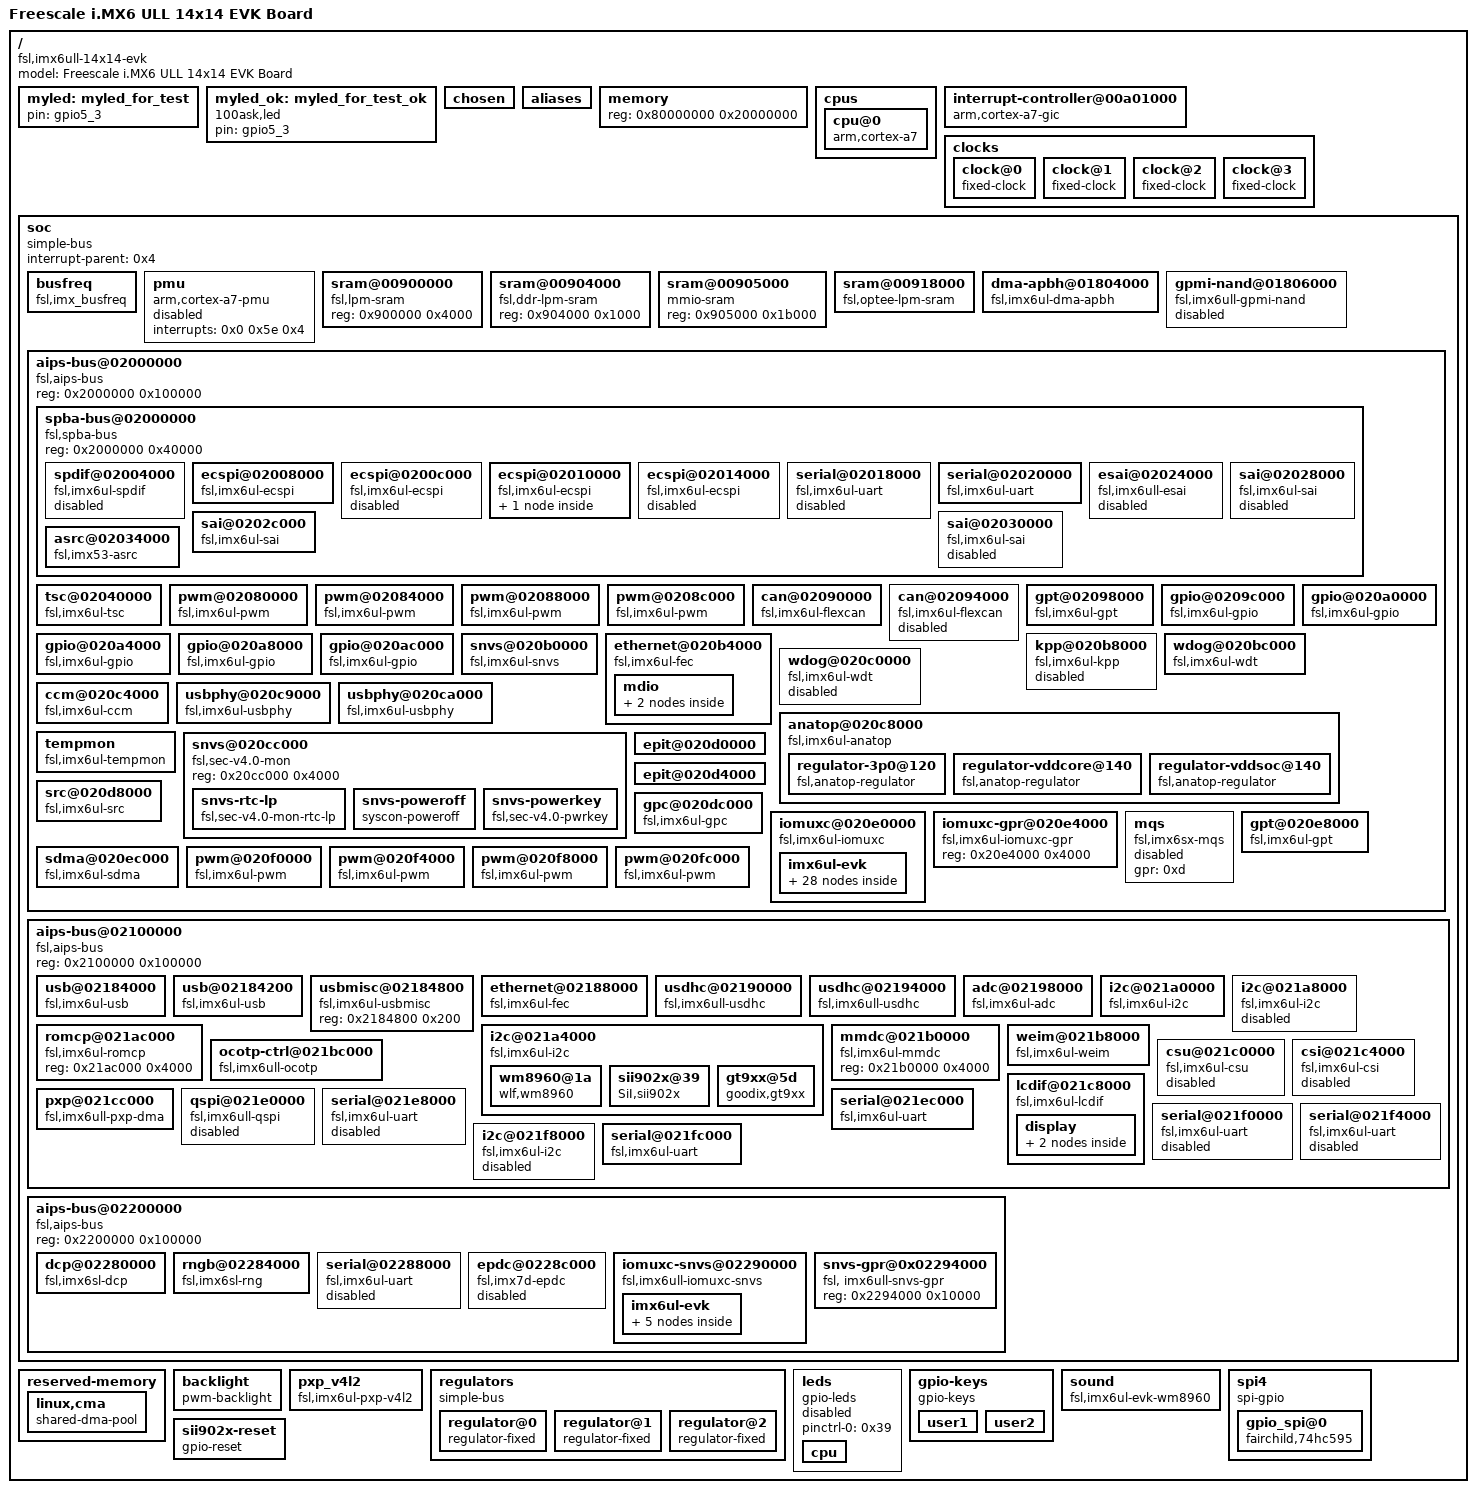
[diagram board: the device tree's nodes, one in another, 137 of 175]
/dts-v1/;

/ {
	#address-cells = <0x1>;
	#size-cells = <0x1>;
	model = "Freescale i.MX6 ULL 14x14 EVK Board";
	compatible = "fsl,imx6ull-14x14-evk", "fsl,imx6ull";

	myled: myled_for_test {
		pin = "gpio5_3";
	};

	myled_ok: myled_for_test_ok {
		compatible = "100ask,led";
		pin = "gpio5_3";
	};

	chosen {
		stdout-path = "/soc/aips-bus@02000000/spba-bus@02000000/serial@02020000";
	};

	aliases {
		can0 = "/soc/aips-bus@02000000/can@02090000";
		can1 = "/soc/aips-bus@02000000/can@02094000";
		ethernet0 = "/soc/aips-bus@02100000/ethernet@02188000";
		ethernet1 = "/soc/aips-bus@02000000/ethernet@020b4000";
		gpio0 = "/soc/aips-bus@02000000/gpio@0209c000";
		gpio1 = "/soc/aips-bus@02000000/gpio@020a0000";
		gpio2 = "/soc/aips-bus@02000000/gpio@020a4000";
		gpio3 = "/soc/aips-bus@02000000/gpio@020a8000";
		gpio4 = "/soc/aips-bus@02000000/gpio@020ac000";
		i2c0 = "/soc/aips-bus@02100000/i2c@021a0000";
		i2c1 = "/soc/aips-bus@02100000/i2c@021a4000";
		i2c2 = "/soc/aips-bus@02100000/i2c@021a8000";
		i2c3 = "/soc/aips-bus@02100000/i2c@021f8000";
		mmc0 = "/soc/aips-bus@02100000/usdhc@02190000";
		mmc1 = "/soc/aips-bus@02100000/usdhc@02194000";
		serial0 = "/soc/aips-bus@02000000/spba-bus@02000000/serial@02020000";
		serial1 = "/soc/aips-bus@02100000/serial@021e8000";
		serial2 = "/soc/aips-bus@02100000/serial@021ec000";
		serial3 = "/soc/aips-bus@02100000/serial@021f0000";
		serial4 = "/soc/aips-bus@02100000/serial@021f4000";
		serial5 = "/soc/aips-bus@02100000/serial@021fc000";
		serial6 = "/soc/aips-bus@02000000/spba-bus@02000000/serial@02018000";
		serial7 = "/soc/aips-bus@02200000/serial@02288000";
		spi0 = "/soc/aips-bus@02000000/spba-bus@02000000/ecspi@02008000";
		spi1 = "/soc/aips-bus@02000000/spba-bus@02000000/ecspi@0200c000";
		spi2 = "/soc/aips-bus@02000000/spba-bus@02000000/ecspi@02010000";
		spi3 = "/soc/aips-bus@02000000/spba-bus@02000000/ecspi@02014000";
		usbphy0 = "/soc/aips-bus@02000000/usbphy@020c9000";
		usbphy1 = "/soc/aips-bus@02000000/usbphy@020ca000";
	};

	memory {
		device_type = "memory";
		reg = <0x80000000 0x20000000>;
	};

	cpus {
		#address-cells = <0x1>;
		#size-cells = <0x0>;

		cpu@0 {
			compatible = "arm,cortex-a7";
			device_type = "cpu";
			reg = <0x0>;
			clock-latency = <0xee6c>;
			operating-points = <0xdbba0 0x137478 0xc15c0 0x12b128 0x80e80 0x11edd8 0x60ae0 0xfa3e8 0x30570 0xe7ef0>;
			fsl,soc-operating-points = <0xdbba0 0x11edd8 0xc15c0 0x11edd8 0x80e80 0x11edd8 0x60ae0 0x11edd8 0x30570 0x11edd8>;
			fsl,low-power-run;
			clocks = <0x1 0x5d 0x1 0x1a 0x1 0x26 0x1 0xdb 0x1 0x38 0x1 0x39 0x1 0x19 0x1 0x12 0x1 0xb 0x1 0x4 0x1 0x3>;
			clock-names = "arm", "pll2_bus", "pll2_pfd2_396m", "secondary_sel", "step", "pll1_sw", "pll1_sys", "pll1_bypass", "pll1", "pll1_bypass_src", "osc";
			arm-supply = <0x2>;
			soc-supply = <0x3>;
		};
	};

	interrupt-controller@00a01000 {
		compatible = "arm,cortex-a7-gic";
		#interrupt-cells = <0x3>;
		interrupt-controller;
		reg = <0xa01000 0x1000 0xa02000 0x100>;
		linux,phandle = <0x1e>;
		phandle = <0x1e>;
	};

	clocks {
		#address-cells = <0x1>;
		#size-cells = <0x0>;

		clock@0 {
			compatible = "fixed-clock";
			reg = <0x0>;
			#clock-cells = <0x0>;
			clock-frequency = <0x8000>;
			clock-output-names = "ckil";
			linux,phandle = <0x16>;
			phandle = <0x16>;
		};

		clock@1 {
			compatible = "fixed-clock";
			reg = <0x1>;
			#clock-cells = <0x0>;
			clock-frequency = <0x16e3600>;
			clock-output-names = "osc";
			linux,phandle = <0x17>;
			phandle = <0x17>;
		};

		clock@2 {
			compatible = "fixed-clock";
			reg = <0x2>;
			#clock-cells = <0x0>;
			clock-frequency = <0x0>;
			clock-output-names = "ipp_di0";
			linux,phandle = <0x18>;
			phandle = <0x18>;
		};

		clock@3 {
			compatible = "fixed-clock";
			reg = <0x3>;
			#clock-cells = <0x0>;
			clock-frequency = <0x0>;
			clock-output-names = "ipp_di1";
			linux,phandle = <0x19>;
			phandle = <0x19>;
		};
	};

	soc {
		#address-cells = <0x1>;
		#size-cells = <0x1>;
		compatible = "simple-bus";
		interrupt-parent = <0x4>;
		ranges;

		busfreq {
			compatible = "fsl,imx_busfreq";
			clocks = <0x1 0x26 0x1 0x35 0x1 0x1a 0x1 0x5d 0x1 0x1b 0x1 0x55 0x1 0x3c 0x1 0x5e 0x1 0x3e 0x1 0x3 0x1 0x60 0x1 0xd4 0x1 0x56 0x1 0x3d 0x1 0x5f 0x1 0x3f 0x1 0x38 0x1 0xa3 0x1 0x4 0x1 0x12 0x1 0x19 0x1 0x39 0x1 0xb>;
			clock-names = "pll2_pfd2_396m", "pll2_198m", "pll2_bus", "arm", "pll3_usb_otg", "periph", "periph_pre", "periph_clk2", "periph_clk2_sel", "osc", "ahb", "ocram", "periph2", "periph2_pre", "periph2_clk2", "periph2_clk2_sel", "step", "mmdc", "pll1_bypass_src", "pll1_bypass", "pll1_sys", "pll1_sw", "pll1";
			fsl,max_ddr_freq = <0x17d78400>;
		};

		pmu {
			compatible = "arm,cortex-a7-pmu";
			interrupts = <0x0 0x5e 0x4>;
			status = "disabled";
		};

		sram@00900000 {
			compatible = "fsl,lpm-sram";
			reg = <0x900000 0x4000>;
		};

		sram@00904000 {
			compatible = "fsl,ddr-lpm-sram";
			reg = <0x904000 0x1000>;
		};

		sram@00905000 {
			compatible = "mmio-sram";
			reg = <0x905000 0x1b000>;
			linux,phandle = <0x5>;
			phandle = <0x5>;
		};

		sram@00918000 {
			compatible = "fsl,optee-lpm-sram";
			reg = <0x918000 0x8000>;
			overw_reg = <0x5 0x905000 0x13000>;
		};

		dma-apbh@01804000 {
			compatible = "fsl,imx6ul-dma-apbh", "fsl,imx28-dma-apbh";
			reg = <0x1804000 0x2000>;
			interrupts = <0x0 0xd 0x4 0x0 0xd 0x4 0x0 0xd 0x4 0x0 0xd 0x4>;
			interrupt-names = "gpmi0", "gpmi1", "gpmi2", "gpmi3";
			#dma-cells = <0x1>;
			dma-channels = <0x4>;
			clocks = <0x1 0x80>;
			linux,phandle = <0x6>;
			phandle = <0x6>;
		};

		gpmi-nand@01806000 {
			compatible = "fsl,imx6ull-gpmi-nand", "fsl, imx6ul-gpmi-nand";
			#address-cells = <0x1>;
			#size-cells = <0x1>;
			reg = <0x1806000 0x2000 0x1808000 0x4000>;
			reg-names = "gpmi-nand", "bch";
			interrupts = <0x0 0xf 0x4>;
			interrupt-names = "bch";
			clocks = <0x1 0x85 0x1 0x86 0x1 0x84 0x1 0x83 0x1 0xdc>;
			clock-names = "gpmi_io", "gpmi_apb", "gpmi_bch", "gpmi_bch_apb", "per1_bch";
			dmas = <0x6 0x0>;
			dma-names = "rx-tx";
			status = "disabled";
		};

		aips-bus@02000000 {
			compatible = "fsl,aips-bus", "simple-bus";
			#address-cells = <0x1>;
			#size-cells = <0x1>;
			reg = <0x2000000 0x100000>;
			ranges;

			spba-bus@02000000 {
				compatible = "fsl,spba-bus", "simple-bus";
				#address-cells = <0x1>;
				#size-cells = <0x1>;
				reg = <0x2000000 0x40000>;
				ranges;

				spdif@02004000 {
					compatible = "fsl,imx6ul-spdif", "fsl,imx35-spdif";
					reg = <0x2004000 0x4000>;
					interrupts = <0x0 0x34 0x4>;
					dmas = <0x7 0x29 0x12 0x0 0x7 0x2a 0x12 0x0>;
					dma-names = "rx", "tx";
					clocks = <0x1 0xd5 0x1 0x3 0x1 0xbc 0x1 0x0 0x1 0x0 0x1 0x0 0x1 0x64 0x1 0x0 0x1 0x0 0x1 0xbb>;
					clock-names = "core", "rxtx0", "rxtx1", "rxtx2", "rxtx3", "rxtx4", "rxtx5", "rxtx6", "rxtx7", "spba";
					status = "disabled";
				};

				ecspi@02008000 {
					#address-cells = <0x1>;
					#size-cells = <0x0>;
					compatible = "fsl,imx6ul-ecspi", "fsl,imx51-ecspi";
					reg = <0x2008000 0x4000>;
					interrupts = <0x0 0x1f 0x4>;
					clocks = <0x1 0x8b 0x1 0x8b>;
					clock-names = "ipg", "per";
					dmas = <0x7 0x3 0x7 0x1 0x7 0x4 0x7 0x2>;
					dma-names = "rx", "tx";
					status = "okay";
					pinctrl-names = "default";
					pinctrl-0 = <0x8>;
					fsl,spi-num-chipselects = <0x2>;
					cs-gpios = <0x9 0x1a 0x1 0x9 0x18 0x1>;
				};

				ecspi@0200c000 {
					#address-cells = <0x1>;
					#size-cells = <0x0>;
					compatible = "fsl,imx6ul-ecspi", "fsl,imx51-ecspi";
					reg = <0x200c000 0x4000>;
					interrupts = <0x0 0x20 0x4>;
					clocks = <0x1 0x8c 0x1 0x8c>;
					clock-names = "ipg", "per";
					dmas = <0x7 0x5 0x7 0x1 0x7 0x6 0x7 0x2>;
					dma-names = "rx", "tx";
					status = "disabled";
				};

				ecspi@02010000 {
					#address-cells = <0x1>;
					#size-cells = <0x0>;
					compatible = "fsl,imx6ul-ecspi", "fsl,imx51-ecspi";
					reg = <0x2010000 0x4000>;
					interrupts = <0x0 0x21 0x4>;
					clocks = <0x1 0x8d 0x1 0x8d>;
					clock-names = "ipg", "per";
					dmas = <0x7 0x7 0x7 0x1 0x7 0x8 0x7 0x2>;
					dma-names = "rx", "tx";
					status = "okay";
					pinctrl-names = "default";
					pinctrl-0 = <0xa>;
					cs-gpios = <0xb 0x14 0x1>;

					icm20608@0 {
						compatible = "invensense,icm20608";
						interrupt-parent = <0xb>;
						interrupts = <0x1 0x1>;
						spi-max-frequency = <0x7a1200>;
						reg = <0x0>;
					};
				};

				ecspi@02014000 {
					#address-cells = <0x1>;
					#size-cells = <0x0>;
					compatible = "fsl,imx6ul-ecspi", "fsl,imx51-ecspi";
					reg = <0x2014000 0x4000>;
					interrupts = <0x0 0x22 0x4>;
					clocks = <0x1 0x8e 0x1 0x8e>;
					clock-names = "ipg", "per";
					dmas = <0x7 0x9 0x7 0x1 0x7 0xa 0x7 0x2>;
					dma-names = "rx", "tx";
					status = "disabled";
				};

				serial@02018000 {
					compatible = "fsl,imx6ul-uart", "fsl,imx6q-uart", "fsl,imx21-uart";
					reg = <0x2018000 0x4000>;
					interrupts = <0x0 0x27 0x4>;
					clocks = <0x1 0xc9 0x1 0xca>;
					clock-names = "ipg", "per";
					dmas = <0x7 0x2b 0x4 0x0 0x7 0x2c 0x4 0x0>;
					dma-names = "rx", "tx";
					status = "disabled";
				};

				serial@02020000 {
					compatible = "fsl,imx6ul-uart", "fsl,imx6q-uart", "fsl,imx21-uart";
					reg = <0x2020000 0x4000>;
					interrupts = <0x0 0x1a 0x4>;
					clocks = <0x1 0xbd 0x1 0xbe>;
					clock-names = "ipg", "per";
					status = "okay";
					pinctrl-names = "default";
					pinctrl-0 = <0xc>;
				};

				esai@02024000 {
					compatible = "fsl,imx6ull-esai";
					reg = <0x2024000 0x4000>;
					interrupts = <0x0 0x33 0x4>;
					clocks = <0x1 0xe6 0x1 0xe5 0x1 0xe4 0x1 0xe6 0x1 0xbb>;
					clock-names = "core", "mem", "extal", "fsys", "spba";
					dmas = <0x7 0x0 0x15 0x0 0x7 0x2f 0x15 0x0>;
					dma-names = "rx", "tx";
					dma-source = <0xd 0x0 0xe 0x0 0xf>;
					status = "disabled";
				};

				sai@02028000 {
					compatible = "fsl,imx6ul-sai", "fsl,imx6sx-sai";
					reg = <0x2028000 0x4000>;
					interrupts = <0x0 0x61 0x4>;
					clocks = <0x1 0xb3 0x1 0x0 0x1 0xb2 0x1 0x0 0x1 0x0>;
					clock-names = "bus", "mclk0", "mclk1", "mclk2", "mclk3";
					dma-names = "rx", "tx";
					dmas = <0x7 0x23 0x18 0x0 0x7 0x24 0x18 0x0>;
					status = "disabled";
				};

				sai@0202c000 {
					compatible = "fsl,imx6ul-sai", "fsl,imx6sx-sai";
					reg = <0x202c000 0x4000>;
					interrupts = <0x0 0x62 0x4>;
					clocks = <0x1 0xb5 0x1 0x0 0x1 0xb4 0x1 0x0 0x1 0x0>;
					clock-names = "bus", "mclk0", "mclk1", "mclk2", "mclk3";
					dma-names = "rx", "tx";
					dmas = <0x7 0x25 0x18 0x0 0x7 0x26 0x18 0x0>;
					status = "okay";
					pinctrl-names = "default";
					pinctrl-0 = <0xe>;
					assigned-clocks = <0x1 0x47 0x1 0xb4>;
					assigned-clock-parents = <0x1 0x32>;
					assigned-clock-rates = <0x0 0xbb8000>;
					linux,phandle = <0x3a>;
					phandle = <0x3a>;
				};

				sai@02030000 {
					compatible = "fsl,imx6ul-sai", "fsl,imx6sx-sai";
					reg = <0x2030000 0x4000>;
					interrupts = <0x0 0x18 0x4>;
					clocks = <0x1 0xb7 0x1 0x0 0x1 0xb6 0x1 0x0 0x1 0x0>;
					clock-names = "bus", "mclk0", "mclk1", "mclk2", "mclk3";
					dma-names = "rx", "tx";
					dmas = <0x7 0x27 0x18 0x0 0x7 0x28 0x18 0x0>;
					status = "disabled";
				};

				asrc@02034000 {
					compatible = "fsl,imx53-asrc";
					reg = <0x2034000 0x4000>;
					interrupts = <0x0 0x32 0x4>;
					clocks = <0x1 0x81 0x1 0x82 0x1 0x0 0x1 0x0 0x1 0x0 0x1 0x0 0x1 0x0 0x1 0x0 0x1 0x0 0x1 0x0 0x1 0x0 0x1 0x0 0x1 0x0 0x1 0x0 0x1 0x0 0x1 0xbc 0x1 0x0 0x1 0x0 0x1 0xbb>;
					clock-names = "mem", "ipg", "asrck_0", "asrck_1", "asrck_2", "asrck_3", "asrck_4", "asrck_5", "asrck_6", "asrck_7", "asrck_8", "asrck_9", "asrck_a", "asrck_b", "asrck_c", "asrck_d", "asrck_e", "asrck_f", "spba";
					dmas = <0x7 0x11 0x17 0x1 0x7 0x12 0x17 0x1 0x7 0x13 0x17 0x1 0x7 0x14 0x17 0x1 0x7 0x15 0x17 0x1 0x7 0x16 0x17 0x1>;
					dma-names = "rxa", "rxb", "rxc", "txa", "txb", "txc";
					fsl,asrc-rate = <0xbb80>;
					fsl,asrc-width = <0x10>;
					status = "okay";
					linux,phandle = <0x3c>;
					phandle = <0x3c>;
				};
			};

			tsc@02040000 {
				compatible = "fsl,imx6ul-tsc";
				reg = <0x2040000 0x4000 0x219c000 0x4000>;
				interrupts = <0x0 0x3 0x4 0x0 0x65 0x4>;
				clocks = <0x1 0x64 0x1 0x7c>;
				clock-names = "tsc", "adc";
				status = "okay";
				pinctrl-names = "default";
				pinctrl-0 = <0xf>;
				xnur-gpio = <0xb 0x3 0x1>;
				measure-delay-time = <0xfffff>;
				pre-charge-time = <0xffff>;
			};

			pwm@02080000 {
				compatible = "fsl,imx6ul-pwm", "fsl,imx27-pwm";
				reg = <0x2080000 0x4000>;
				interrupts = <0x0 0x53 0x4>;
				clocks = <0x1 0xa7 0x1 0xa7>;
				clock-names = "ipg", "per";
				#pwm-cells = <0x2>;
				pinctrl-names = "default";
				pinctrl-0 = <0x10>;
				status = "okay";
				linux,phandle = <0x38>;
				phandle = <0x38>;
			};

			pwm@02084000 {
				compatible = "fsl,imx6ul-pwm", "fsl,imx27-pwm";
				reg = <0x2084000 0x4000>;
				interrupts = <0x0 0x54 0x4>;
				clocks = <0x1 0x0 0x1 0x0>;
				clock-names = "ipg", "per";
				#pwm-cells = <0x2>;
			};

			pwm@02088000 {
				compatible = "fsl,imx6ul-pwm", "fsl,imx27-pwm";
				reg = <0x2088000 0x4000>;
				interrupts = <0x0 0x55 0x4>;
				clocks = <0x1 0xa9 0x1 0xa9>;
				clock-names = "ipg", "per";
				#pwm-cells = <0x2>;
			};

			pwm@0208c000 {
				compatible = "fsl,imx6ul-pwm", "fsl,imx27-pwm";
				reg = <0x208c000 0x4000>;
				interrupts = <0x0 0x56 0x4>;
				clocks = <0x1 0x0 0x1 0x0>;
				clock-names = "ipg", "per";
				#pwm-cells = <0x2>;
			};

			can@02090000 {
				compatible = "fsl,imx6ul-flexcan", "fsl,imx6q-flexcan";
				reg = <0x2090000 0x4000>;
				interrupts = <0x0 0x6e 0x4>;
				clocks = <0x1 0x94 0x1 0x95>;
				clock-names = "ipg", "per";
				stop-mode = <0xd 0x10 0x1 0x10 0x11>;
				status = "okay";
				pinctrl-names = "default";
				pinctrl-0 = <0x11>;
				xceiver-supply = <0x12>;
			};

			can@02094000 {
				compatible = "fsl,imx6ul-flexcan", "fsl,imx6q-flexcan";
				reg = <0x2094000 0x4000>;
				interrupts = <0x0 0x6f 0x4>;
				clocks = <0x1 0x96 0x1 0x97>;
				clock-names = "ipg", "per";
				stop-mode = <0xd 0x10 0x2 0x10 0x12>;
				status = "disabled";
			};

			gpt@02098000 {
				compatible = "fsl,imx6ul-gpt", "fsl,imx31-gpt";
				reg = <0x2098000 0x4000>;
				interrupts = <0x0 0x37 0x4>;
				clocks = <0x1 0x98 0x1 0xd6>;
				clock-names = "ipg", "osc_per";
			};

			gpio@0209c000 {
				compatible = "fsl,imx6ul-gpio", "fsl,imx35-gpio";
				reg = <0x209c000 0x4000>;
				interrupts = <0x0 0x42 0x4 0x0 0x43 0x4>;
				gpio-controller;
				#gpio-cells = <0x2>;
				interrupt-controller;
				#interrupt-cells = <0x2>;
				linux,phandle = <0xb>;
				phandle = <0xb>;
			};

			gpio@020a0000 {
				compatible = "fsl,imx6ul-gpio", "fsl,imx35-gpio";
				reg = <0x20a0000 0x4000>;
				interrupts = <0x0 0x44 0x4 0x0 0x45 0x4>;
				gpio-controller;
				#gpio-cells = <0x2>;
				interrupt-controller;
				#interrupt-cells = <0x2>;
			};

			gpio@020a4000 {
				compatible = "fsl,imx6ul-gpio", "fsl,imx35-gpio";
				reg = <0x20a4000 0x4000>;
				interrupts = <0x0 0x46 0x4 0x0 0x47 0x4>;
				gpio-controller;
				#gpio-cells = <0x2>;
				interrupt-controller;
				#interrupt-cells = <0x2>;
				linux,phandle = <0x32>;
				phandle = <0x32>;
			};

			gpio@020a8000 {
				compatible = "fsl,imx6ul-gpio", "fsl,imx35-gpio";
				reg = <0x20a8000 0x4000>;
				interrupts = <0x0 0x48 0x4 0x0 0x49 0x4>;
				gpio-controller;
				#gpio-cells = <0x2>;
				interrupt-controller;
				#interrupt-cells = <0x2>;
				linux,phandle = <0x9>;
				phandle = <0x9>;
			};

			gpio@020ac000 {
				compatible = "fsl,imx6ul-gpio", "fsl,imx35-gpio";
				reg = <0x20ac000 0x4000>;
				interrupts = <0x0 0x4a 0x4 0x0 0x4b 0x4>;
				gpio-controller;
				#gpio-cells = <0x2>;
				interrupt-controller;
				#interrupt-cells = <0x2>;
				linux,phandle = <0x15>;
				phandle = <0x15>;
			};

			snvs@020b0000 {
				compatible = "fsl,imx6ul-snvs";
				reg = <0x20b0000 0x4000>;
				interrupts = <0x0 0x4 0x4>;
			};

			ethernet@020b4000 {
				compatible = "fsl,imx6ul-fec", "fsl,imx6q-fec";
				reg = <0x20b4000 0x4000>;
				interrupts = <0x0 0x78 0x4 0x0 0x79 0x4>;
				clocks = <0x1 0x90 0x1 0x91 0x1 0x30 0x1 0x2e 0x1 0x2e>;
				clock-names = "ipg", "ahb", "ptp", "enet_clk_ref", "enet_out";
				stop-mode = <0xd 0x10 0x4>;
				fsl,num-tx-queues = <0x1>;
				fsl,num-rx-queues = <0x1>;
				fsl,magic-packet;
				fsl,wakeup_irq = <0x0>;
				status = "okay";
				pinctrl-names = "default";
				pinctrl-0 = <0x13>;
				phy-mode = "rmii";
				phy-handle = <0x14>;
				phy-reset-gpios = <0x15 0x6 0x1>;
				phy-reset-duration = <0x1a>;

				mdio {
					#address-cells = <0x1>;
					#size-cells = <0x0>;

					ethernet-phy@0 {
						compatible = "ethernet-phy-ieee802.3-c22";
						smsc,disable-energy-detect;
						reg = <0x0>;
						linux,phandle = <0x24>;
						phandle = <0x24>;
					};

					ethernet-phy@1 {
						compatible = "ethernet-phy-ieee802.3-c22";
						smsc,disable-energy-detect;
						reg = <0x1>;
						linux,phandle = <0x14>;
						phandle = <0x14>;
					};
				};
			};

			kpp@020b8000 {
				compatible = "fsl,imx6ul-kpp", "fsl,imx21-kpp";
				reg = <0x20b8000 0x4000>;
				interrupts = <0x0 0x52 0x4>;
				clocks = <0x1 0x0>;
				status = "disabled";
			};

			wdog@020bc000 {
				compatible = "fsl,imx6ul-wdt", "fsl,imx21-wdt";
				reg = <0x20bc000 0x4000>;
				interrupts = <0x0 0x50 0x4>;
				clocks = <0x1 0xd0>;
				status = "okay";
			};

			wdog@020c0000 {
				compatible = "fsl,imx6ul-wdt", "fsl,imx21-wdt";
				reg = <0x20c0000 0x4000>;
				interrupts = <0x0 0x51 0x4>;
				clocks = <0x1 0xd1>;
				status = "disabled";
			};

			ccm@020c4000 {
				compatible = "fsl,imx6ul-ccm";
				reg = <0x20c4000 0x4000>;
				interrupts = <0x0 0x57 0x4 0x0 0x58 0x4>;
				#clock-cells = <0x1>;
				clocks = <0x16 0x17 0x18 0x19>;
				clock-names = "ckil", "osc", "ipp_di0", "ipp_di1";
				assigned-clocks = <0x1 0x32>;
				assigned-clock-rates = <0x2ee00000>;
				linux,phandle = <0x1>;
				phandle = <0x1>;
			};

			anatop@020c8000 {
				compatible = "fsl,imx6ul-anatop", "fsl,imx6q-anatop", "syscon", "simple-bus";
				reg = <0x20c8000 0x1000>;
				interrupts = <0x0 0x31 0x4 0x0 0x36 0x4 0x0 0x7f 0x4>;
				linux,phandle = <0x1b>;
				phandle = <0x1b>;

				regulator-3p0@120 {
					compatible = "fsl,anatop-regulator";
					regulator-name = "vdd3p0";
					regulator-min-microvolt = <0x280de8>;
					regulator-max-microvolt = <0x33e140>;
					anatop-reg-offset = <0x120>;
					anatop-vol-bit-shift = <0x8>;
					anatop-vol-bit-width = <0x5>;
					anatop-min-bit-val = <0x0>;
					anatop-min-voltage = <0x280de8>;
					anatop-max-voltage = <0x33e140>;
					anatop-enable-bit = <0x0>;
					linux,phandle = <0x1a>;
					phandle = <0x1a>;
				};

				regulator-vddcore@140 {
					compatible = "fsl,anatop-regulator";
					regulator-name = "cpu";
					regulator-min-microvolt = <0xb1008>;
					regulator-max-microvolt = <0x162010>;
					regulator-always-on;
					anatop-reg-offset = <0x140>;
					anatop-vol-bit-shift = <0x0>;
					anatop-vol-bit-width = <0x5>;
					anatop-delay-reg-offset = <0x170>;
					anatop-delay-bit-shift = <0x18>;
					anatop-delay-bit-width = <0x2>;
					anatop-min-bit-val = <0x1>;
					anatop-min-voltage = <0xb1008>;
					anatop-max-voltage = <0x162010>;
					linux,phandle = <0x2>;
					phandle = <0x2>;
				};

				regulator-vddsoc@140 {
					compatible = "fsl,anatop-regulator";
					regulator-name = "vddsoc";
					regulator-min-microvolt = <0xb1008>;
					regulator-max-microvolt = <0x162010>;
					regulator-always-on;
					anatop-reg-offset = <0x140>;
					anatop-vol-bit-shift = <0x12>;
					anatop-vol-bit-width = <0x5>;
					anatop-delay-reg-offset = <0x170>;
					anatop-delay-bit-shift = <0x1c>;
					anatop-delay-bit-width = <0x2>;
					anatop-min-bit-val = <0x1>;
					anatop-min-voltage = <0xb1008>;
					anatop-max-voltage = <0x162010>;
					linux,phandle = <0x3>;
					phandle = <0x3>;
				};
			};

			usbphy@020c9000 {
				compatible = "fsl,imx6ul-usbphy", "fsl,imx23-usbphy";
				reg = <0x20c9000 0x1000>;
				interrupts = <0x0 0x2c 0x4>;
				clocks = <0x1 0x20>;
				phy-3p0-supply = <0x1a>;
				fsl,anatop = <0x1b>;
				tx-d-cal = <0x5>;
				linux,phandle = <0x20>;
				phandle = <0x20>;
			};

			usbphy@020ca000 {
				compatible = "fsl,imx6ul-usbphy", "fsl,imx23-usbphy";
				reg = <0x20ca000 0x1000>;
				interrupts = <0x0 0x2d 0x4>;
				clocks = <0x1 0x21>;
				phy-3p0-supply = <0x1a>;
				fsl,anatop = <0x1b>;
				tx-d-cal = <0x5>;
				linux,phandle = <0x22>;
				phandle = <0x22>;
			};

			tempmon {
				compatible = "fsl,imx6ul-tempmon", "fsl,imx6sx-tempmon";
				interrupts = <0x0 0x31 0x4>;
				fsl,tempmon = <0x1b>;
				fsl,tempmon-data = <0x1c>;
				clocks = <0x1 0x1b>;
			};

			snvs@020cc000 {
				compatible = "fsl,sec-v4.0-mon", "syscon", "simple-mfd";
				reg = <0x20cc000 0x4000>;
				linux,phandle = <0x1d>;
				phandle = <0x1d>;

				snvs-rtc-lp {
					compatible = "fsl,sec-v4.0-mon-rtc-lp";
					regmap = <0x1d>;
					offset = <0x34>;
					interrupts = <0x0 0x13 0x4 0x0 0x14 0x4>;
				};

				snvs-poweroff {
					compatible = "syscon-poweroff";
					regmap = <0x1d>;
					offset = <0x38>;
					mask = <0x61>;
				};

				snvs-powerkey {
					compatible = "fsl,sec-v4.0-pwrkey";
					regmap = <0x1d>;
					interrupts = <0x0 0x4 0x4>;
					linux,keycode = <0x74>;
					wakeup-source;
				};
			};

			epit@020d0000 {
				reg = <0x20d0000 0x4000>;
				interrupts = <0x0 0x38 0x4>;
			};

			epit@020d4000 {
				reg = <0x20d4000 0x4000>;
				interrupts = <0x0 0x39 0x4>;
			};

			src@020d8000 {
				compatible = "fsl,imx6ul-src", "fsl,imx51-src";
				reg = <0x20d8000 0x4000>;
				interrupts = <0x0 0x5b 0x4 0x0 0x60 0x4>;
				#reset-cells = <0x1>;
			};

			gpc@020dc000 {
				compatible = "fsl,imx6ul-gpc", "fsl,imx6q-gpc";
				reg = <0x20dc000 0x4000>;
				interrupt-controller;
				#interrupt-cells = <0x3>;
				interrupts = <0x0 0x59 0x4>;
				interrupt-parent = <0x1e>;
				fsl,mf-mix-wakeup-irq = <0xfc00000 0x7d00 0x0 0x1400640>;
				fsl,cpu_pupscr_sw2iso = <0x1>;
				fsl,cpu_pupscr_sw = <0x0>;
				fsl,cpu_pdnscr_iso2sw = <0x1>;
				fsl,cpu_pdnscr_iso = <0x1>;
				fsl,ldo-bypass = <0x0>;
				linux,phandle = <0x4>;
				phandle = <0x4>;
			};

			iomuxc@020e0000 {
				compatible = "fsl,imx6ul-iomuxc";
				reg = <0x20e0000 0x4000>;
				pinctrl-names = "default";
				pinctrl-0 = <0x1f>;

				imx6ul-evk {

					hoggrp-1 {
						fsl,pins = <0x90 0x31c 0x0 0x5 0x0 0x17059 0x5c 0x2e8 0x4b8 0x2 0x0 0x17059 0x1c 0x60 0x0 0x5 0x0 0x110a0>;
						linux,phandle = <0x1f>;
						phandle = <0x1f>;
					};

					hdmigrp {
						fsl,pins = <0x8c 0x318 0x0 0x5 0x0 0x59>;
						linux,phandle = <0x2a>;
						phandle = <0x2a>;
					};

					lcdif_tsc_int {
						fsl,pins = <0x70 0x2fc 0x0 0x5 0x0 0x10b0>;
						linux,phandle = <0x2d>;
						phandle = <0x2d>;
					};

					enet1grp {
						fsl,pins;
						linux,phandle = <0x23>;
						phandle = <0x23>;
					};

					enet2grp {
						fsl,pins = <0x74 0x300 0x580 0x1 0x0 0x1b0b0 0x78 0x304 0x0 0x1 0x0 0x1b0b0 0xec 0x378 0x0 0x0 0x0 0x1b0b0 0x100 0x38c 0x0 0x0 0x0 0x1b0b0 0xe4 0x370 0x0 0x0 0x0 0x1b0b0 0xe8 0x374 0x0 0x0 0x0 0x1b0b0 0xf8 0x384 0x0 0x0 0x0 0x1b0b0 0xf0 0x37c 0x0 0x0 0x0 0x1b0b0 0xf4 0x380 0x0 0x0 0x0 0x1b0b0 0xfc 0x388 0x57c 0x4 0x2 0x4001b031 0xcc 0x358 0x0 0x0 0x0 0x1b0b0 0xe0 0x36c 0x0 0x0 0x0 0x1b0b0 0xc4 0x350 0x0 0x0 0x0 0x1b0b0 0xc8 0x354 0x0 0x0 0x0 0x1b0b0 0xd8 0x364 0x0 0x0 0x0 0x1b0b0 0xd0 0x35c 0x0 0x0 0x0 0x1b0b0 0xd4 0x360 0x0 0x0 0x0 0x1b0b0 0xdc 0x368 0x574 0x4 0x2 0x4001b031>;
						linux,phandle = <0x13>;
						phandle = <0x13>;
					};

					flexcan1grp {
						fsl,pins = <0xac 0x338 0x0 0x2 0x0 0x10b0 0xb0 0x33c 0x584 0x2 0x0 0x10b0>;
						linux,phandle = <0x11>;
						phandle = <0x11>;
					};

					i2c1grp {
						fsl,pins = <0xb4 0x340 0x5a4 0x2 0x1 0x4001b8b0 0xb8 0x344 0x5a8 0x2 0x2 0x4001b8b0>;
						linux,phandle = <0x28>;
						phandle = <0x28>;
					};

					i2c2grp {
						fsl,pins = <0xbc 0x348 0x5ac 0x2 0x2 0x4001b8b0 0xc0 0x34c 0x5b0 0x2 0x2 0x4001b8b0>;
						linux,phandle = <0x29>;
						phandle = <0x29>;
					};

					ecspi3 {
						fsl,pins = <0x9c 0x328 0x55c 0x8 0x0 0x10b0 0xa0 0x32c 0x558 0x8 0x0 0x10b0 0x98 0x324 0x554 0x8 0x0 0x10b0 0x94 0x320 0x0 0x5 0x0 0x10b0 0x60 0x2ec 0x0 0x5 0x0 0x10b0>;
						linux,phandle = <0xa>;
						phandle = <0xa>;
					};

					ecspi1 {
						fsl,pins = <0x1f4 0x480 0x534 0x3 0x1 0x10b0 0x1fc 0x488 0x53c 0x3 0x1 0x10b0 0x200 0x48c 0x538 0x3 0x1 0x10b0 0x1f8 0x484 0x0 0x5 0x0 0x10b0 0x1f0 0x47c 0x0 0x5 0x0 0x10b0>;
						linux,phandle = <0x8>;
						phandle = <0x8>;
					};

					uart3grp {
						fsl,pins = <0xa4 0x330 0x0 0x0 0x0 0x1b0b1 0xa8 0x334 0x634 0x0 0x1 0x1b0b1>;
						linux,phandle = <0x34>;
						phandle = <0x34>;
					};

					uart1grp {
						fsl,pins = <0x84 0x310 0x0 0x0 0x0 0x1b0b1 0x88 0x314 0x624 0x0 0x3 0x1b0b1>;
						linux,phandle = <0xc>;
						phandle = <0xc>;
					};

					uart6grp {
						fsl,pins = <0x1d4 0x460 0x0 0x8 0x0 0x1b0b1 0x1d8 0x464 0x64c 0x8 0x3 0x1b0b1>;
						linux,phandle = <0x36>;
						phandle = <0x36>;
					};

					sai2grp {
						fsl,pins = <0x50 0x2dc 0x5f8 0x2 0x0 0x17088 0x4c 0x2d8 0x5fc 0x2 0x0 0x17088 0x58 0x2e4 0x0 0x2 0x0 0x11088 0x54 0x2e0 0x5f4 0x2 0x0 0x11088 0x48 0x2d4 0x5f0 0x2 0x0 0x17088>;
						linux,phandle = <0xe>;
						phandle = <0xe>;
					};

					tscgrp {
						fsl,pins = <0x60 0x2ec 0x0 0x5 0x0 0xb0 0x64 0x2f0 0x0 0x5 0x0 0xb0 0x68 0x2f4 0x0 0x5 0x0 0xb0 0x6c 0x2f8 0x0 0x5 0x0 0xb0>;
						linux,phandle = <0xf>;
						phandle = <0xf>;
					};

					usdhc1grp {
						fsl,pins = <0x1bc 0x448 0x0 0x0 0x0 0x17059 0x1c0 0x44c 0x0 0x0 0x0 0x10071 0x1c4 0x450 0x0 0x0 0x0 0x17059 0x1c8 0x454 0x0 0x0 0x0 0x17059 0x1cc 0x458 0x0 0x0 0x0 0x17059 0x1d0 0x45c 0x0 0x0 0x0 0x17059>;
						linux,phandle = <0x25>;
						phandle = <0x25>;
					};

					usdhc1grp100mhz {
						fsl,pins = <0x1bc 0x448 0x0 0x0 0x0 0x170b9 0x1c0 0x44c 0x0 0x0 0x0 0x100b9 0x1c4 0x450 0x0 0x0 0x0 0x170b9 0x1c8 0x454 0x0 0x0 0x0 0x170b9 0x1cc 0x458 0x0 0x0 0x0 0x170b9 0x1d0 0x45c 0x0 0x0 0x0 0x170b9>;
					};

					usdhc1grp200mhz {
						fsl,pins = <0x1bc 0x448 0x0 0x0 0x0 0x170f9 0x1c0 0x44c 0x0 0x0 0x0 0x100f9 0x1c4 0x450 0x0 0x0 0x0 0x170f9 0x1c8 0x454 0x0 0x0 0x0 0x170f9 0x1cc 0x458 0x0 0x0 0x0 0x170f9 0x1d0 0x45c 0x0 0x0 0x0 0x170f9>;
					};

					usdhc2grp {
						fsl,pins = <0x178 0x404 0x670 0x1 0x2 0x10069 0x17c 0x408 0x678 0x1 0x2 0x17059 0x180 0x40c 0x67c 0x1 0x2 0x17059 0x184 0x410 0x680 0x1 0x2 0x17059 0x188 0x414 0x684 0x1 0x1 0x17059 0x18c 0x418 0x688 0x1 0x2 0x17059>;
					};

					usdhc2grp_8bit {
						fsl,pins = <0x178 0x404 0x670 0x1 0x2 0x10069 0x17c 0x408 0x678 0x1 0x2 0x17059 0x180 0x40c 0x67c 0x1 0x2 0x17059 0x184 0x410 0x680 0x1 0x2 0x17059 0x188 0x414 0x684 0x1 0x1 0x17059 0x18c 0x418 0x688 0x1 0x2 0x17059 0x190 0x41c 0x68c 0x1 0x1 0x17059 0x194 0x420 0x690 0x1 0x1 0x17059 0x198 0x424 0x694 0x1 0x1 0x17059 0x19c 0x428 0x698 0x1 0x1 0x17059>;
						linux,phandle = <0x26>;
						phandle = <0x26>;
					};

					usdhc2grp_8bit_100mhz {
						fsl,pins = <0x178 0x404 0x670 0x1 0x2 0x100b9 0x17c 0x408 0x678 0x1 0x2 0x170b9 0x180 0x40c 0x67c 0x1 0x2 0x170b9 0x184 0x410 0x680 0x1 0x2 0x170b9 0x188 0x414 0x684 0x1 0x1 0x170b9 0x18c 0x418 0x688 0x1 0x2 0x170b9 0x190 0x41c 0x68c 0x1 0x1 0x170b9 0x194 0x420 0x690 0x1 0x1 0x170b9 0x198 0x424 0x694 0x1 0x1 0x170b9 0x19c 0x428 0x698 0x1 0x1 0x170b9>;
					};

					usdhc2grp_8bit_200mhz {
						fsl,pins = <0x178 0x404 0x670 0x1 0x2 0x100f9 0x17c 0x408 0x678 0x1 0x2 0x170f9 0x180 0x40c 0x67c 0x1 0x2 0x170f9 0x184 0x410 0x680 0x1 0x2 0x170f9 0x188 0x414 0x684 0x1 0x1 0x170f9 0x18c 0x418 0x688 0x1 0x2 0x170f9 0x190 0x41c 0x68c 0x1 0x1 0x170f9 0x194 0x420 0x690 0x1 0x1 0x170f9 0x198 0x424 0x694 0x1 0x1 0x170f9 0x19c 0x428 0x698 0x1 0x1 0x170f9>;
					};

					lcdifdatgrp {
						fsl,pins = <0x118 0x3a4 0x0 0x0 0x0 0x79 0x11c 0x3a8 0x0 0x0 0x0 0x79 0x120 0x3ac 0x0 0x0 0x0 0x79 0x124 0x3b0 0x0 0x0 0x0 0x79 0x128 0x3b4 0x0 0x0 0x0 0x79 0x12c 0x3b8 0x0 0x0 0x0 0x79 0x130 0x3bc 0x0 0x0 0x0 0x79 0x134 0x3c0 0x0 0x0 0x0 0x79 0x138 0x3c4 0x0 0x0 0x0 0x79 0x13c 0x3c8 0x0 0x0 0x0 0x79 0x140 0x3cc 0x0 0x0 0x0 0x79 0x144 0x3d0 0x0 0x0 0x0 0x79 0x148 0x3d4 0x0 0x0 0x0 0x79 0x14c 0x3d8 0x0 0x0 0x0 0x79 0x150 0x3dc 0x0 0x0 0x0 0x79 0x154 0x3e0 0x0 0x0 0x0 0x79 0x158 0x3e4 0x0 0x0 0x0 0x79 0x15c 0x3e8 0x0 0x0 0x0 0x79 0x160 0x3ec 0x0 0x0 0x0 0x79 0x164 0x3f0 0x0 0x0 0x0 0x79 0x168 0x3f4 0x0 0x0 0x0 0x79 0x16c 0x3f8 0x0 0x0 0x0 0x79 0x170 0x3fc 0x0 0x0 0x0 0x79 0x174 0x400 0x0 0x0 0x0 0x79>;
						linux,phandle = <0x2e>;
						phandle = <0x2e>;
					};

					lcdifdatgrp_16bits {
						fsl,pins = <0x118 0x3a4 0x0 0x0 0x0 0x79 0x11c 0x3a8 0x0 0x0 0x0 0x79 0x120 0x3ac 0x0 0x0 0x0 0x79 0x124 0x3b0 0x0 0x0 0x0 0x79 0x128 0x3b4 0x0 0x0 0x0 0x79 0x12c 0x3b8 0x0 0x0 0x0 0x79 0x130 0x3bc 0x0 0x0 0x0 0x79 0x134 0x3c0 0x0 0x0 0x0 0x79 0x138 0x3c4 0x0 0x0 0x0 0x79 0x13c 0x3c8 0x0 0x0 0x0 0x79 0x140 0x3cc 0x0 0x0 0x0 0x79 0x144 0x3d0 0x0 0x0 0x0 0x79 0x148 0x3d4 0x0 0x0 0x0 0x79 0x14c 0x3d8 0x0 0x0 0x0 0x79 0x150 0x3dc 0x0 0x0 0x0 0x79 0x154 0x3e0 0x0 0x0 0x0 0x79>;
					};

					lcdifctrlgrp {
						fsl,pins = <0x104 0x390 0x0 0x0 0x0 0x79 0x108 0x394 0x0 0x0 0x0 0x79 0x10c 0x398 0x5dc 0x0 0x0 0x79 0x110 0x39c 0x0 0x0 0x0 0x79>;
						linux,phandle = <0x2f>;
						phandle = <0x2f>;
					};

					pwm1grp {
						fsl,pins = <0x7c 0x308 0x0 0x0 0x0 0x110b0>;
						linux,phandle = <0x10>;
						phandle = <0x10>;
					};

					lcdifresetgrp {
						fsl,pins = <0x114 0x3a0 0x0 0x5 0x0 0x1b0b0>;
						linux,phandle = <0x30>;
						phandle = <0x30>;
					};

					adc1grp {
						fsl,pins = <0x68 0x2f4 0x0 0x5 0x0 0x10b1 0x6c 0x2f8 0x0 0x5 0x0 0x10b1>;
						linux,phandle = <0x27>;
						phandle = <0x27>;
					};
				};
			};

			iomuxc-gpr@020e4000 {
				compatible = "fsl,imx6ul-iomuxc-gpr", "fsl,imx6q-iomuxc-gpr", "syscon";
				reg = <0x20e4000 0x4000>;
				linux,phandle = <0xd>;
				phandle = <0xd>;
			};

			mqs {
				compatible = "fsl,imx6sx-mqs";
				gpr = <0xd>;
				status = "disabled";
			};

			gpt@020e8000 {
				compatible = "fsl,imx6ul-gpt", "fsl,imx31-gpt";
				reg = <0x20e8000 0x4000>;
				interrupts = <0x0 0x6d 0x4>;
				clocks = <0x1 0x0 0x1 0x0>;
				clock-names = "ipg", "per";
			};

			sdma@020ec000 {
				compatible = "fsl,imx6ul-sdma", "fsl,imx35-sdma";
				reg = <0x20ec000 0x4000>;
				interrupts = <0x0 0x2 0x4>;
				clocks = <0x1 0xb8 0x1 0xb8>;
				clock-names = "ipg", "ahb";
				#dma-cells = <0x3>;
				iram = <0x5>;
				fsl,sdma-ram-script-name = "imx/sdma/sdma-imx6q.bin";
				linux,phandle = <0x7>;
				phandle = <0x7>;
			};

			pwm@020f0000 {
				compatible = "fsl,imx6ul-pwm", "fsl,imx27-pwm";
				reg = <0x20f0000 0x4000>;
				interrupts = <0x0 0x72 0x4>;
				clocks = <0x1 0x0 0x1 0x0>;
				clock-names = "ipg", "per";
				#pwm-cells = <0x2>;
			};

			pwm@020f4000 {
				compatible = "fsl,imx6ul-pwm", "fsl,imx27-pwm";
				reg = <0x20f4000 0x4000>;
				interrupts = <0x0 0x73 0x4>;
				clocks = <0x1 0x0 0x1 0x0>;
				clock-names = "ipg", "per";
				#pwm-cells = <0x2>;
			};

			pwm@020f8000 {
				compatible = "fsl,imx6ul-pwm", "fsl,imx27-pwm";
				reg = <0x20f8000 0x4000>;
				interrupts = <0x0 0x74 0x4>;
				clocks = <0x1 0x0 0x1 0x0>;
				clock-names = "ipg", "per";
				#pwm-cells = <0x2>;
			};

			pwm@020fc000 {
				compatible = "fsl,imx6ul-pwm", "fsl,imx27-pwm";
				reg = <0x20fc000 0x4000>;
				interrupts = <0x0 0x75 0x4>;
				clocks = <0x1 0x0 0x1 0x0>;
				clock-names = "ipg", "per";
				#pwm-cells = <0x2>;
			};
		};

		aips-bus@02100000 {
			compatible = "fsl,aips-bus", "simple-bus";
			#address-cells = <0x1>;
			#size-cells = <0x1>;
			reg = <0x2100000 0x100000>;
			ranges;

			usb@02184000 {
				compatible = "fsl,imx6ul-usb", "fsl,imx27-usb";
				reg = <0x2184000 0x200>;
				interrupts = <0x0 0x2b 0x4>;
				clocks = <0x1 0xcd>;
				fsl,usbphy = <0x20>;
				fsl,usbmisc = <0x21 0x0>;
				fsl,anatop = <0x1b>;
				ahb-burst-config = <0x0>;
				tx-burst-size-dword = <0x10>;
				rx-burst-size-dword = <0x10>;
				status = "okay";
				dr_mode = "otg";
				srp-disable;
				hnp-disable;
				adp-disable;
			};

			usb@02184200 {
				compatible = "fsl,imx6ul-usb", "fsl,imx27-usb";
				reg = <0x2184200 0x200>;
				interrupts = <0x0 0x2a 0x4>;
				clocks = <0x1 0xcd>;
				fsl,usbphy = <0x22>;
				fsl,usbmisc = <0x21 0x1>;
				ahb-burst-config = <0x0>;
				tx-burst-size-dword = <0x10>;
				rx-burst-size-dword = <0x10>;
				status = "okay";
				dr_mode = "host";
				disable-over-current;
			};

			usbmisc@02184800 {
				#index-cells = <0x1>;
				compatible = "fsl,imx6ul-usbmisc", "fsl,imx6q-usbmisc";
				reg = <0x2184800 0x200>;
				linux,phandle = <0x21>;
				phandle = <0x21>;
			};

			ethernet@02188000 {
				compatible = "fsl,imx6ul-fec", "fsl,imx6q-fec";
				reg = <0x2188000 0x4000>;
				interrupts = <0x0 0x76 0x4 0x0 0x77 0x4>;
				clocks = <0x1 0x90 0x1 0x91 0x1 0x30 0x1 0x2c 0x1 0x2c>;
				clock-names = "ipg", "ahb", "ptp", "enet_clk_ref", "enet_out";
				stop-mode = <0xd 0x10 0x3>;
				fsl,num-tx-queues = <0x1>;
				fsl,num-rx-queues = <0x1>;
				fsl,magic-packet;
				fsl,wakeup_irq = <0x0>;
				status = "okay";
				pinctrl-names = "default";
				pinctrl-0 = <0x23>;
				phy-mode = "rmii";
				phy-handle = <0x24>;
				phy-reset-gpios = <0x15 0x9 0x1>;
				phy-reset-duration = <0x1a>;
			};

			usdhc@02190000 {
				compatible = "fsl,imx6ull-usdhc", "fsl,imx6sx-usdhc";
				reg = <0x2190000 0x4000>;
				interrupts = <0x0 0x16 0x4>;
				clocks = <0x1 0xce 0x1 0xce 0x1 0xce>;
				clock-names = "ipg", "ahb", "per";
				assigned-clocks = <0x1 0x40 0x1 0xce>;
				assigned-clock-parents = <0x1 0x26>;
				assigned-clock-rates = <0x0 0x7de2900>;
				bus-width = <0x4>;
				fsl,tuning-step = <0x2>;
				status = "okay";
				pinctrl-names = "default";
				pinctrl-0 = <0x25>;
				cd-gpios = <0xb 0x13 0x1>;
				keep-power-in-suspend;
				enable-sdio-wakeup;
			};

			usdhc@02194000 {
				compatible = "fsl,imx6ull-usdhc", "fsl,imx6sx-usdhc";
				reg = <0x2194000 0x4000>;
				interrupts = <0x0 0x17 0x4>;
				clocks = <0x1 0xcf 0x1 0xcf 0x1 0xcf>;
				clock-names = "ipg", "ahb", "per";
				assigned-clocks = <0x1 0x41 0x1 0xcf>;
				assigned-clock-parents = <0x1 0x26>;
				assigned-clock-rates = <0x0 0x7de2900>;
				bus-width = <0x8>;
				fsl,tuning-step = <0x2>;
				status = "okay";
				pinctrl-names = "default";
				pinctrl-0 = <0x26>;
				non-removable;
			};

			adc@02198000 {
				compatible = "fsl,imx6ul-adc", "fsl,vf610-adc";
				reg = <0x2198000 0x4000>;
				interrupts = <0x0 0x64 0x4>;
				clocks = <0x1 0x7b>;
				num-channels = <0x5>;
				clock-names = "adc";
				status = "okay";
				pinctrl-names = "default";
				pinctrl-0 = <0x27>;
				vref-supply = <0x12>;
			};

			i2c@021a0000 {
				#address-cells = <0x1>;
				#size-cells = <0x0>;
				compatible = "fsl,imx6ul-i2c", "fsl,imx21-i2c";
				reg = <0x21a0000 0x4000>;
				interrupts = <0x0 0x24 0x4>;
				clocks = <0x1 0x9c>;
				status = "okay";
				clock-frequency = <0x186a0>;
				pinctrl-names = "default";
				pinctrl-0 = <0x28>;
			};

			i2c@021a4000 {
				#address-cells = <0x1>;
				#size-cells = <0x0>;
				compatible = "fsl,imx6ul-i2c", "fsl,imx21-i2c";
				reg = <0x21a4000 0x4000>;
				interrupts = <0x0 0x25 0x4>;
				clocks = <0x1 0x9d>;
				status = "okay";
				clock_frequency = <0x186a0>;
				pinctrl-names = "default";
				pinctrl-0 = <0x29>;

				wm8960@1a {
					compatible = "wlf,wm8960";
					reg = <0x1a>;
					clocks = <0x1 0xb4>;
					clock-names = "mclk";
					wlf,shared-lrclk;
					linux,phandle = <0x3b>;
					phandle = <0x3b>;
				};

				sii902x@39 {
					compatible = "SiI,sii902x";
					pinctrl-names = "default";
					reset-names = "sii902x";
					pinctrl-0 = <0x2a>;
					resets = <0x2b>;
					interrupt-parent = <0xb>;
					interrupts = <0x12 0x2>;
					mode_str = "1280x720M@60";
					bits-per-pixel = <0x10>;
					reg = <0x39>;
					status = "okay";
				};

				gt9xx@5d {
					compatible = "goodix,gt9xx";
					reg = <0x5d>;
					status = "okay";
					interrupt-parent = <0xb>;
					interrupts = <0x5 0x2>;
					pinctrl-names = "default";
					pinctrl-0 = <0x2c 0x2d>;
					reset-gpios = <0x15 0x2 0x1>;
					irq-gpios = <0xb 0x5 0x2>;
					irq-flags = <0x2>;
					touchscreen-max-id = <0x5>;
					touchscreen-size-x = <0x320>;
					touchscreen-size-y = <0x1e0>;
					touchscreen-max-w = <0x400>;
					touchscreen-max-p = <0x400>;
					goodix,type-a-report = <0x0>;
					goodix,driver-send-cfg = <0x0>;
					goodix,create-wr-node = <0x1>;
					goodix,wakeup-with-reset = <0x0>;
					goodix,resume-in-workqueue = <0x0>;
					goodix,int-sync = <0x0>;
					goodix,swap-x2y = <0x0>;
					goodix,esd-protect = <0x0>;
					goodix,pen-suppress-finger = <0x0>;
					goodix,auto-update = <0x0>;
					goodix,auto-update-cfg = <0x0>;
					goodix,power-off-sleep = <0x0>;
					goodix,cfg-group0 = [6b 00 04 58 02 05 0d 00 01 0f 28 0f 50 32 03 05 00 00 00 00 00 00 00 00 00 00 00 8a 2a 0c 45 47 0c 08 00 00 00 40 03 2c 00 01 00 00 00 03 64 32 00 00 00 28 64 94 d5 02 07 00 00 04 95 2c 00 8b 34 00 82 3f 00 7d 4c 00 7a 5b 00 7a 00 00 00 00 00 00 00 00 00 00 00 00 00 00 00 00 00 00 00 00 00 00 00 00 00 00 00 00 00 00 00 00 00 00 00 00 18 16 14 12 10 0e 0c 0a 08 06 04 02 ff ff 00 00 00 00 00 00 00 00 00 00 00 00 00 00 00 00 16 18 1c 1d 1e 1f 20 21 22 24 13 12 10 0f 0a 08 06 04 02 00 ff ff ff ff ff ff 00 00 00 00 00 00 00 00 00 00 00 00 00 00 00 00 79 01];
					goodix,cfg-group1 = [97 e0 01 10 01 05 0d 00 01 00 00 05 5a 46 53 11 00 00 11 11 14 14 14 22 0a 04 00 00 00 00 00 00 53 00 14 00 00 84 00 00 3c 00 00 64 1e 28 87 27 08 32 34 05 0d 20 33 60 11 02 24 00 00 64 80 80 14 02 00 00 54 89 68 85 6d 82 72 80 76 7d 7b 7b 00 00 00 00 00 00 00 f0 50 3c ff ff 07 00 00 00 02 14 14 03 04 00 21 64 0a 00 00 00 00 00 00 00 00 00 00 00 00 00 00 00 00 00 00 00 00 00 00 00 00 00 32 20 50 3c 3c 00 00 00 00 00 0d 06 0c 05 0b 04 0a 03 ff ff ff ff ff ff 00 01 02 03 04 05 06 07 08 09 0a 0b 0c 0d ff ff ff ff ff ff ff ff ff ff ff ff 00 00 00 00 00 00 00 00 00 00 00 00 00 00 3c 00 05 1e 00 02 2a 1e 19 14 02 00 03 0a 05 00 00 00 00 00 00 00 01 ff ff 86 22 03 00 00 33 00 0f 00 00 00 50 3c 50 00 00 00 00 2a 01];
					goodix,cfg-group2 = [00 20 03 e0 01 05 3c 00 01 08 28 0c 50 32 03 05 00 00 00 00 00 00 00 17 19 1e 14 8b 2b 0d 33 35 0c 08 00 00 00 9a 03 11 00 01 00 00 00 00 00 32 00 00 00 20 58 94 c5 02 00 00 00 04 b0 23 00 93 2b 00 7b 35 00 69 41 00 5b 4f 00 5b 00 00 00 00 00 00 00 00 00 00 00 00 00 00 00 00 00 00 00 00 00 00 00 00 00 00 00 00 00 00 00 00 00 00 00 00 02 04 06 08 0a 0c 0e 10 12 14 16 18 1a ff 00 00 00 00 00 00 00 00 00 00 00 00 00 00 00 00 00 02 04 06 08 0a 0c 0f 10 12 13 16 18 1c 1d 1e 1f 20 21 22 24 26 ff ff ff ff 00 00 00 ff ff ff ff ff ff ff ff ff ff ff ff ff 48 01];
				};
			};

			i2c@021a8000 {
				#address-cells = <0x1>;
				#size-cells = <0x0>;
				compatible = "fsl,imx6ul-i2c", "fsl,imx21-i2c";
				reg = <0x21a8000 0x4000>;
				interrupts = <0x0 0x26 0x4>;
				clocks = <0x1 0x9e>;
				status = "disabled";
			};

			romcp@021ac000 {
				compatible = "fsl,imx6ul-romcp", "syscon";
				reg = <0x21ac000 0x4000>;
			};

			mmdc@021b0000 {
				compatible = "fsl,imx6ul-mmdc", "fsl,imx6q-mmdc";
				reg = <0x21b0000 0x4000>;
			};

			weim@021b8000 {
				compatible = "fsl,imx6ul-weim", "fsl,imx6q-weim";
				reg = <0x21b8000 0x4000>;
				interrupts = <0x0 0xe 0x4>;
				clocks = <0x1 0x0>;
			};

			ocotp-ctrl@021bc000 {
				compatible = "fsl,imx6ull-ocotp", "syscon";
				reg = <0x21bc000 0x4000>;
				clocks = <0x1 0xa5>;
				linux,phandle = <0x1c>;
				phandle = <0x1c>;
			};

			csu@021c0000 {
				compatible = "fsl,imx6ul-csu";
				reg = <0x21c0000 0x4000>;
				interrupts = <0x0 0x15 0x4>;
				status = "disabled";
			};

			csi@021c4000 {
				compatible = "fsl,imx6ul-csi", "fsl,imx6s-csi";
				reg = <0x21c4000 0x4000>;
				interrupts = <0x0 0x7 0x4>;
				clocks = <0x1 0x0 0x1 0x8a 0x1 0x0>;
				clock-names = "disp-axi", "csi_mclk", "disp_dcic";
				status = "disabled";
			};

			lcdif@021c8000 {
				compatible = "fsl,imx6ul-lcdif", "fsl,imx28-lcdif";
				reg = <0x21c8000 0x4000>;
				interrupts = <0x0 0x5 0x4>;
				clocks = <0x1 0xa2 0x1 0xa1 0x1 0x0>;
				clock-names = "pix", "axi", "disp_axi";
				status = "okay";
				pinctrl-names = "default";
				pinctrl-0 = <0x2e 0x2f 0x30>;
				display = <0x31>;
				reset-gpios = <0x32 0x4 0x1>;

				display {
					bits-per-pixel = <0x18>;
					bus-width = <0x18>;
					linux,phandle = <0x31>;
					phandle = <0x31>;

					display-timings {
						native-mode = <0x33>;

						timing0_1024x768 {
							clock-frequency = <0x2faf080>;
							hactive = <0x400>;
							vactive = <0x258>;
							hfront-porch = <0xa0>;
							hback-porch = <0x8c>;
							hsync-len = <0x14>;
							vback-porch = <0x14>;
							vfront-porch = <0xc>;
							vsync-len = <0x3>;
							hsync-active = <0x0>;
							vsync-active = <0x0>;
							de-active = <0x1>;
							pixelclk-active = <0x0>;
							linux,phandle = <0x33>;
							phandle = <0x33>;
						};
					};
				};
			};

			pxp@021cc000 {
				compatible = "fsl,imx6ull-pxp-dma", "fsl,imx7d-pxp-dma";
				reg = <0x21cc000 0x4000>;
				interrupts = <0x0 0x8 0x4 0x0 0x12 0x4>;
				clocks = <0x1 0x0 0x1 0xaf>;
				clock-names = "pxp_ipg", "pxp_axi";
				status = "okay";
			};

			qspi@021e0000 {
				#address-cells = <0x1>;
				#size-cells = <0x0>;
				compatible = "fsl,imx6ull-qspi", "fsl,imx6ul-qspi";
				reg = <0x21e0000 0x4000 0x60000000 0x10000000>;
				reg-names = "QuadSPI", "QuadSPI-memory";
				interrupts = <0x0 0x6b 0x4>;
				clocks = <0x1 0xb0 0x1 0xb0>;
				clock-names = "qspi_en", "qspi";
				status = "disabled";
			};

			serial@021e8000 {
				compatible = "fsl,imx6ul-uart", "fsl,imx6q-uart", "fsl,imx21-uart";
				reg = <0x21e8000 0x4000>;
				interrupts = <0x0 0x1b 0x4>;
				clocks = <0x1 0xbf 0x1 0xc0>;
				clock-names = "ipg", "per";
				dmas = <0x7 0x1b 0x4 0x0 0x7 0x1c 0x4 0x0>;
				dma-names = "rx", "tx";
				status = "disabled";
			};

			serial@021ec000 {
				compatible = "fsl,imx6ul-uart", "fsl,imx6q-uart", "fsl,imx21-uart";
				reg = <0x21ec000 0x4000>;
				interrupts = <0x0 0x1c 0x4>;
				clocks = <0x1 0xc1 0x1 0xc2>;
				clock-names = "ipg", "per";
				dmas = <0x7 0x1d 0x4 0x0 0x7 0x1e 0x4 0x0>;
				dma-names = "rx", "tx";
				status = "okay";
				pinctrl-names = "default";
				pinctrl-0 = <0x34 0x35>;
				rs485-rts-active-high;
				rs485-rx-during-tx;
				rs485-rts-delay = <0x64 0x64>;
				linux,rs485-enabled-at-boot-time;
			};

			serial@021f0000 {
				compatible = "fsl,imx6ul-uart", "fsl,imx6q-uart", "fsl,imx21-uart";
				reg = <0x21f0000 0x4000>;
				interrupts = <0x0 0x1d 0x4>;
				clocks = <0x1 0xc3 0x1 0xc4>;
				clock-names = "ipg", "per";
				dmas = <0x7 0x1f 0x4 0x0 0x7 0x20 0x4 0x0>;
				dma-names = "rx", "tx";
				status = "disabled";
			};

			serial@021f4000 {
				compatible = "fsl,imx6ul-uart", "fsl,imx6q-uart", "fsl,imx21-uart";
				reg = <0x21f4000 0x4000>;
				interrupts = <0x0 0x1e 0x4>;
				clocks = <0x1 0xc5 0x1 0xc6>;
				clock-names = "ipg", "per";
				dmas = <0x7 0x21 0x4 0x0 0x7 0x22 0x4 0x0>;
				dma-names = "rx", "tx";
				status = "disabled";
			};

			i2c@021f8000 {
				#address-cells = <0x1>;
				#size-cells = <0x0>;
				compatible = "fsl,imx6ul-i2c", "fsl,imx21-i2c";
				reg = <0x21f8000 0x4000>;
				interrupts = <0x0 0x23 0x4>;
				clocks = <0x1 0x9f>;
				status = "disabled";
			};

			serial@021fc000 {
				compatible = "fsl,imx6ul-uart", "fsl,imx6q-uart", "fsl,imx21-uart";
				reg = <0x21fc000 0x4000>;
				interrupts = <0x0 0x11 0x4>;
				clocks = <0x1 0xc7 0x1 0xc8>;
				clock-names = "ipg", "per";
				dmas = <0x7 0x0 0x4 0x0 0x7 0x2f 0x4 0x0>;
				dma-names = "rx", "tx";
				status = "okay";
				pinctrl-names = "default";
				pinctrl-0 = <0x36>;
			};
		};

		aips-bus@02200000 {
			compatible = "fsl,aips-bus", "simple-bus";
			#address-cells = <0x1>;
			#size-cells = <0x1>;
			reg = <0x2200000 0x100000>;
			ranges;

			dcp@02280000 {
				compatible = "fsl,imx6sl-dcp";
				reg = <0x2280000 0x4000>;
				interrupts = <0x0 0x2e 0x4 0x0 0x2f 0x4 0x0 0x30 0x4>;
				clocks = <0x1 0xe7>;
				clock-names = "dcp";
			};

			rngb@02284000 {
				compatible = "fsl,imx6sl-rng", "fsl,imx-rng", "imx-rng";
				reg = <0x2284000 0x4000>;
				interrupts = <0x0 0x6 0x4>;
				clocks = <0x1 0x0>;
			};

			serial@02288000 {
				compatible = "fsl,imx6ul-uart", "fsl,imx6q-uart", "fsl,imx21-uart";
				reg = <0x2288000 0x4000>;
				interrupts = <0x0 0x28 0x4>;
				clocks = <0x1 0xcb 0x1 0xcc>;
				clock-names = "ipg", "per";
				dmas = <0x7 0x2d 0x4 0x0 0x7 0x2e 0x4 0x0>;
				dma-names = "rx", "tx";
				status = "disabled";
			};

			epdc@0228c000 {
				compatible = "fsl,imx7d-epdc";
				interrupts = <0x0 0x70 0x4>;
				reg = <0x228c000 0x4000>;
				clocks = <0x1 0xeb 0x1 0xec>;
				clock-names = "epdc_axi", "epdc_pix";
				status = "disabled";
			};

			iomuxc-snvs@02290000 {
				compatible = "fsl,imx6ull-iomuxc-snvs";
				reg = <0x2290000 0x10000>;
				pinctrl-names = "default_snvs";
				pinctrl-0 = <0x37>;

				imx6ul-evk {

					hoggrp-2 {
						fsl,pins = <0x2c 0x70 0x0 0x5 0x0 0x1b0b0 0x20 0x64 0x0 0x5 0x0 0x1b0b0 0xc 0x50 0x0 0x5 0x0 0x110a0>;
						linux,phandle = <0x37>;
						phandle = <0x37>;
					};

					tscresetgrp {
						fsl,pins = <0x10 0x54 0x0 0x5 0x0 0x110a0>;
						linux,phandle = <0x2c>;
						phandle = <0x2c>;
					};

					spi4grp {
						fsl,pins = <0x0 0x44 0x0 0x5 0x0 0x70a1 0x4 0x48 0x0 0x5 0x0 0x70a1 0x24 0x68 0x0 0x5 0x0 0x70a1 0x28 0x6c 0x0 0x5 0x0 0x80000000>;
						linux,phandle = <0x3d>;
						phandle = <0x3d>;
					};

					ledgrp {
						fsl,pins = <0x14 0x58 0x0 0x5 0x0 0x110a0>;
						linux,phandle = <0x39>;
						phandle = <0x39>;
					};

					uart3_rs485 {
						fsl,pins = <0x8 0x4c 0x0 0x5 0x0 0x1b0b0>;
						linux,phandle = <0x35>;
						phandle = <0x35>;
					};
				};
			};

			snvs-gpr@0x02294000 {
				compatible = "fsl, imx6ull-snvs-gpr";
				reg = <0x2294000 0x10000>;
			};
		};
	};

	reserved-memory {
		#address-cells = <0x1>;
		#size-cells = <0x1>;
		ranges;

		linux,cma {
			compatible = "shared-dma-pool";
			reusable;
			size = <0x14000000>;
			linux,cma-default;
		};
	};

	backlight {
		compatible = "pwm-backlight";
		pwms = <0x38 0x0 0x3e8>;
		brightness-levels = <0x0 0x1 0x2 0x3 0x4 0x5 0x6 0x8 0xa>;
		default-brightness-level = <0x8>;
		status = "okay";
	};

	pxp_v4l2 {
		compatible = "fsl,imx6ul-pxp-v4l2", "fsl,imx6sx-pxp-v4l2", "fsl,imx6sl-pxp-v4l2";
		status = "okay";
	};

	regulators {
		compatible = "simple-bus";
		#address-cells = <0x1>;
		#size-cells = <0x0>;

		regulator@0 {
			compatible = "regulator-fixed";
			reg = <0x0>;
			regulator-name = "can-3v3";
			regulator-min-microvolt = <0x325aa0>;
			regulator-max-microvolt = <0x325aa0>;
			linux,phandle = <0x12>;
			phandle = <0x12>;
		};

		regulator@1 {
			compatible = "regulator-fixed";
			regulator-name = "ltemodule-pwr";
			regulator-min-microvolt = <0x39fbc0>;
			regulator-max-microvolt = <0x39fbc0>;
			gpios = <0x15 0x5 0x0>;
			enable-active-high;
			regulator-boot-on;
		};

		regulator@2 {
			compatible = "regulator-fixed";
			regulator-name = "wifi-pwr";
			regulator-min-microvolt = <0x325aa0>;
			regulator-max-microvolt = <0x325aa0>;
			gpios = <0xb 0xa 0x1>;
			regulator-boot-on;
		};
	};

	leds {
		compatible = "gpio-leds";
		pinctrl-names = "default";
		pinctrl-0 = <0x39>;
		status = "disabled";

		cpu {
			label = "cpu";
			gpios = <0x15 0x3 0x1>;
			default-state = "on";
			linux,default-trigger = "heartbeat";
		};
	};

	gpio-keys {
		compatible = "gpio-keys";
		pinctrl-names = "default";

		user1 {
			label = "User1 Button";
			gpios = <0x15 0x1 0x1>;
			gpio-key,wakeup;
			linux,code = <0x2>;
		};

		user2 {
			label = "User2 Button";
			gpios = <0x9 0xe 0x1>;
			gpio-key,wakeup;
			linux,code = <0x3>;
		};
	};

	sound {
		compatible = "fsl,imx6ul-evk-wm8960", "fsl,imx-audio-wm8960";
		model = "wm8960-audio";
		cpu-dai = <0x3a>;
		audio-codec = <0x3b>;
		asrc-controller = <0x3c>;
		codec-master;
		gpr = <0xd 0x4 0x100000 0x100000>;
		hp-det = <0x3 0x0>;
		audio-routing = "Headphone Jack", "HP_L", "Headphone Jack", "HP_R", "Ext Spk", "SPK_LP", "Ext Spk", "SPK_LN", "Ext Spk", "SPK_RP", "Ext Spk", "SPK_RN", "LINPUT2", "Mic Jack", "LINPUT3", "Mic Jack", "RINPUT1", "Main MIC", "RINPUT2", "Main MIC", "Mic Jack", "MICB", "Main MIC", "MICB", "CPU-Playback", "ASRC-Playback", "Playback", "CPU-Playback", "ASRC-Capture", "CPU-Capture", "CPU-Capture", "Capture";
		status = "okay";
	};

	spi4 {
		compatible = "spi-gpio";
		pinctrl-names = "default";
		pinctrl-0 = <0x3d>;
		pinctrl-assert-gpios = <0x15 0x8 0x1>;
		status = "okay";
		gpio-sck = <0x15 0xb 0x0>;
		gpio-mosi = <0x15 0xa 0x0>;
		cs-gpios = <0x15 0x7 0x0>;
		num-chipselects = <0x1>;
		#address-cells = <0x1>;
		#size-cells = <0x0>;

		gpio_spi@0 {
			compatible = "fairchild,74hc595";
			gpio-controller;
			#gpio-cells = <0x2>;
			reg = <0x0>;
			registers-number = <0x1>;
			registers-default = [57];
			spi-max-frequency = <0x2710>;
			linux,phandle = <0x3e>;
			phandle = <0x3e>;
		};
	};

	sii902x-reset {
		compatible = "gpio-reset";
		reset-gpios = <0x3e 0x1 0x1>;
		reset-delay-us = <0x186a0>;
		#reset-cells = <0x0>;
		status = "okay";
		linux,phandle = <0x2b>;
		phandle = <0x2b>;
	};
};
